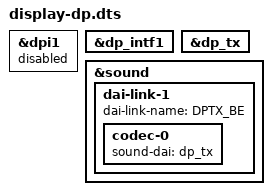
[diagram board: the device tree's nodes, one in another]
/dts-v1/;
/plugin/;

/ {
	fragment@0 {
		target = <&dpi1>;
		__overlay__ {
			status = "disabled";
		};
	};

	fragment@1 {
		target = <&dp_intf1>;
		__overlay__ {
			status = "okay";
		};
	};

	fragment@2 {
		target = <&dp_tx>;
		__overlay__ {
			status = "okay";
		};
	};

	fragment@3 {
		target = <&sound>;
		__overlay__ {
			dai-link-1 {
				dai-link-name = "DPTX_BE";

				codec-0 {
					sound-dai = <&dp_tx>;
				};
			};
		};
	};
};

